AUTOSAR XML (schema 314)
package /ComponentType
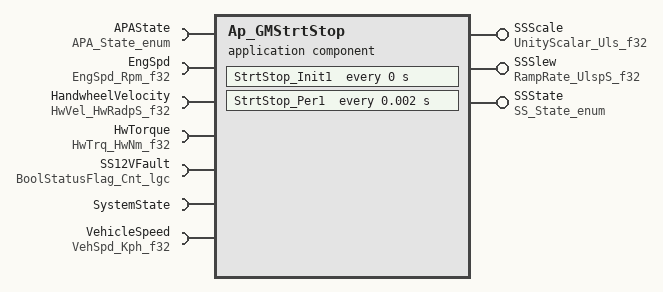
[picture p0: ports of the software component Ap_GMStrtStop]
  application software component type Ap_GMStrtStop
    provide port SSScale: unqueued-sender-com-spec{data-element=Uls_f32, can-invalidate=false, init-value=D_ONE_ULS_F32}, provided-interface=UnityScalar_Uls_f32
    provide port SSSlew: unqueued-sender-com-spec{data-element=UlspS_f32, can-invalidate=false, init-value=D_ONE_ULS_F32}, provided-interface=RampRate_UlspS_f32
    provide port SSState: unqueued-sender-com-spec{data-element=State_enum, can-invalidate=false, init-value=D_SSSTATEINIT_CNT_U08}, provided-interface=SS_State_enum
    7 x require port:
      APAState: unqueued-receiver-com-spec{data-element=State_enum, init-value=D_APASTATEINIT_CNT_U08}, required-interface=APA_State_enum
      EngSpd: unqueued-receiver-com-spec{data-element=Rpm_f32, init-value=D_ZERO_ULS_F32}, required-interface=EngSpd_Rpm_f32
      HandwheelVelocity: unqueued-receiver-com-spec{data-element=HwRadpS_f32, init-value=D_ZERO_ULS_F32}, required-interface=HwVel_HwRadpS_f32
      HwTorque: unqueued-receiver-com-spec{data-element=HwNm_f32, init-value=D_ZERO_ULS_F32}, required-interface=HwTrq_HwNm_f32
      SS12VFault: unqueued-receiver-com-spec{data-element=Cnt_lgc, init-value=D_FALSE_CNT_LGC}, required-interface=BoolStatusFlag_Cnt_lgc
      SystemState: required-interface=SystemState
      VehicleSpeed: unqueued-receiver-com-spec{data-element=Kph_f32, init-value=D_ZERO_ULS_F32}, required-interface=VehSpd_Kph_f32
  internal behavior Ap_GMStrtStop_InternalBehavior: component=Ap_GMStrtStop
    timing event StrtStop_Init1_InitEvent: start-on-event=StrtStop_Init1, period=0
    timing event TMT_StrtStop_Per1: mode-dependency=dependent-on-mode=[SystemState.Mode.DISABLE, SystemState.Mode.OFF, SystemState.Mode.WARMINIT], start-on-event=StrtStop_Per1, period=0.002
    port-api-options:
      enable-take-address=false, indirect-api=false, port=APAState
      enable-take-address=false, indirect-api=false, port=EngSpd
      enable-take-address=false, indirect-api=false, port=HandwheelVelocity
      enable-take-address=false, indirect-api=false, port=HwTorque
      enable-take-address=false, indirect-api=false, port=SS12VFault
      enable-take-address=false, indirect-api=false, port=SSScale
      enable-take-address=false, indirect-api=false, port=SSSlew
      enable-take-address=false, indirect-api=false, port=SSState
      enable-take-address=false, indirect-api=false, port=SystemState
      enable-take-address=false, indirect-api=false, port=VehicleSpeed
    runnable StrtStop_Init1
    runnable StrtStop_Per1
      6 x data read access:
        READ_APAState_State_enum: data-element=APAState.State_enum
        READ_EngSpd_Rpm_f32: data-element=EngSpd.Rpm_f32
        READ_HandwheelVelocity_HwRadpS_f32: data-element=HandwheelVelocity.HwRadpS_f32
        READ_HwTorque_HwNm_f32: data-element=HwTorque.HwNm_f32
        READ_SS12VFault_Cnt_lgc: data-element=SS12VFault.Cnt_lgc
        READ_VehicleSpeed_Kph_f32: data-element=VehicleSpeed.Kph_f32
      data write access WRITE_SSScale_Uls_f32: data-element=SSScale.Uls_f32
      data write access WRITE_SSSlew_UlspS_f32: data-element=SSSlew.UlspS_f32
      data write access WRITE_SSState_State_enum: data-element=SSState.State_enum
  swc implementation Ap_GMStrtStop_Implementation: behavior=Ap_GMStrtStop_InternalBehavior
    code-descriptors:
      code Code: type=SRC
